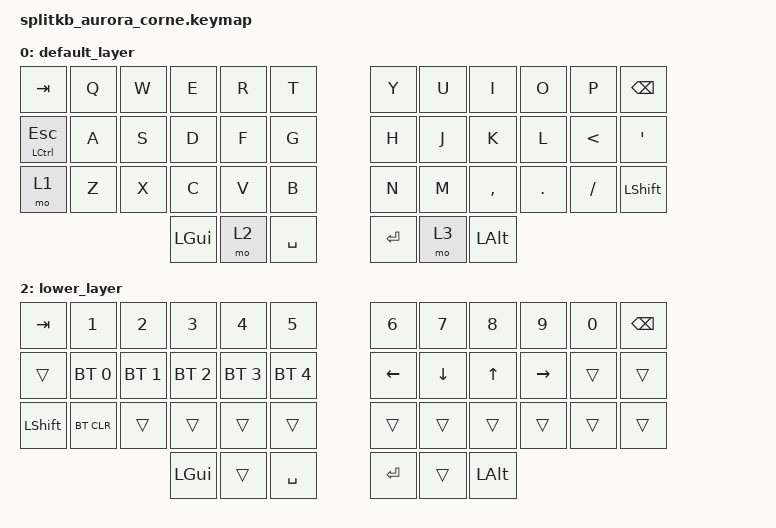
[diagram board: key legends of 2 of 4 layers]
/*
 * Copyright (c) 2020 The ZMK Contributors
 *
 * SPDX-License-Identifier: MIT
 */

#include <behaviors.dtsi>
#include <dt-bindings/zmk/keys.h>
#include <dt-bindings/zmk/bt.h>
#include "../helper.h"
#include "../char/spanish.dtsi"

/ {
        keymap {
                compatible = "zmk,keymap";

                default_layer {
                        bindings = <
   &kp TAB        &kp Q        &kp W        &kp E        &kp R        &kp T                     &kp Y             &kp U                  &kp I                 &kp O                  &kp P            &kp BSPC
   &mt LCTRL ESC  &kp A        &kp S        &kp D        &kp F        &kp G                     &kp H             &kp J                  &kp K                 &kp L                  &kp LESS_THAN    &kp SQT
   &mo 1          &kp Z        &kp X        &kp C        &kp V        &kp B                     &kp N             &kp M                  &kp COMMA             &kp DOT                &kp SLASH        &kp LSHFT
                                               &kp LGUI     &mo 2        &kp SPACE           &kp RET       &mo 3      &kp LALT
                        >;
                };
                //&mo 1
                middle_layer {
                        bindings = <
   &kp TAB        &kp Q        &kp W        &kp E        &kp R        &kp T                     &kp Y             &kp U                  &kp I                 &kp O                  &kp P            &kp BSPC
   &mt LCTRL ESC  &kp A        &kp S        &kp D        &kp F        &kp G                     &kp LEFT_BRACKET  &kp RIGHT_BRACKET      &kp LEFT_BRACE        &kp RIGHT_BRACE        &kp &trans       &kp SQT
   &mo 1          &kp Z        &kp X        &kp C        &kp V        &kp B                     &kp SEMICOLON     &kp M                  &kp COMMA             &kp DOT                &kp PIPE         &caps_word
                                               &kp LGUI     &trans        &kp SPACE           &kp RET      &trans      &kp LALT
                        >;
                };
                //&mo 2
                lower_layer {
                        bindings = <
   &kp TAB        &kp N1       &kp N2       &kp N3       &kp N4       &kp N5                    &kp N6            &kp N7                 &kp N8                &kp N9                 &kp N0           &kp BSPC
   &trans         &bt BT_SEL 0 &bt BT_SEL 1 &bt BT_SEL 2 &bt BT_SEL 3 &bt BT_SEL 4              &kp LEFT          &kp DOWN               &kp UP                &kp RIGHT              &trans           &trans
   &kp LSHFT      &bt BT_CLR   &trans       &trans       &trans       &trans                    &trans            &trans                 &trans                &trans                 &trans           &trans
                                               &kp LGUI     &trans       &kp SPACE           &kp RET       &trans     &kp LALT
                        >;
                };
                //&mo 3
                raise_layer {
                        bindings = <
   &kp  TAB       &kp EXCL     &kp AT_SIGN  &kp HASH     &kp DOLLAR   &kp PERCENT               &kp AMPERSAND     &kp ASTERISK           &kp LEFT_PARENTHESIS  &kp RIGHT_PARENTHESIS  &kp EQUAL        &kp BSPC
   &kp LCTRL      &trans       &trans       &trans       &trans       &trans                    &kp MINUS         &kp &trans             &kp &trans            &kp &trans             &kp GREATER_THAN &kp GRAVE
   &kp LSHFT      &trans       &trans       &trans       &trans       &trans                    &kp LS(SLASH)     &kp &trans             &kp &trans            &kp &trans             &kp &trans       &kp &trans
                                               &kp LGUI     &trans       &kp SPACE           &kp RET       &trans     &kp LALT
                        >;
                };
        };
};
